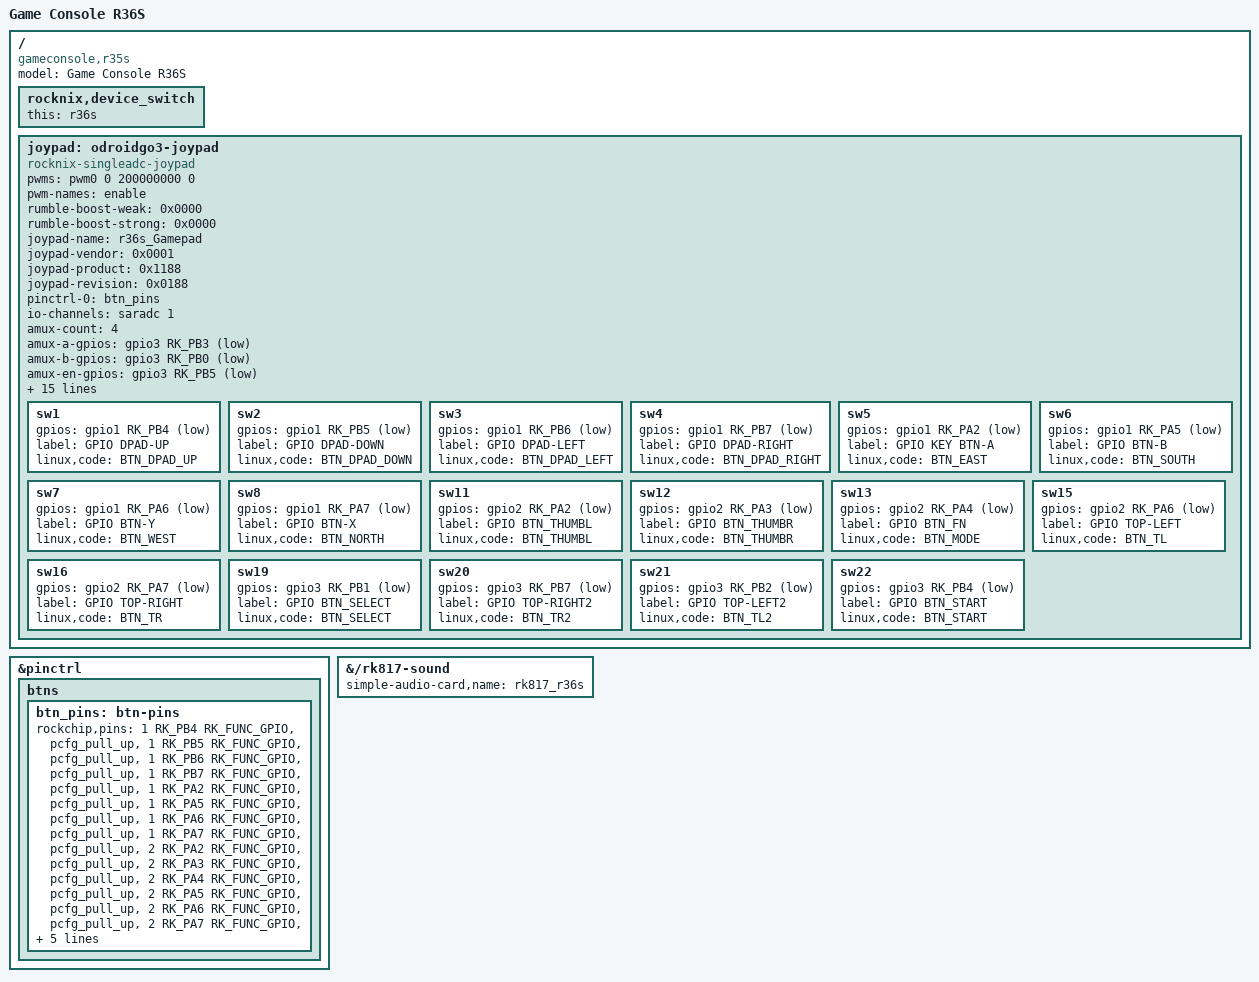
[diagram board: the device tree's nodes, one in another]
// SPDX-License-Identifier: (GPL-2.0+ OR MIT)
/*
 * # Copyright (C) 2022-24 JELOS (https://github.com/JustEnoughLinuxOS)
 */

/dts-v1/;
#include "rk3326-gameconsole-r3xs.dtsi"
#include "rk3326-device-group-r36.dtsi"

/ {
	model = "Game Console R36S";
	compatible = "gameconsole,r35s", "gameconsole,r36s", "rockchip,rk3326";

	rocknix,device_switch {
		this = "r36s";
	};

	joypad: odroidgo3-joypad {
                compatible = "rocknix-singleadc-joypad";
                pwms = <&pwm0 0 200000000 0>;		 
                pwm-names = "enable";
                rumble-boost-weak = <0x0000>;
                rumble-boost-strong = <0x0000>;
		 
                joypad-name = "r36s_Gamepad";
                joypad-vendor = <0x0001>;
                joypad-product = <0x1188>;
                joypad-revision = <0x0188>;

		status = "okay";

		/* gpio pincontrol setup */
                pinctrl-names = "default";
                pinctrl-0 = <&btn_pins>;

		/* Analog mux define */
		io-channel-names = "amux_adc";
		io-channels = <&saradc 1>;

		/* adc mux channel count */
		amux-count = <4>;
		/* adc mux select(a,b) gpio */
		amux-a-gpios = <&gpio3 RK_PB3 GPIO_ACTIVE_LOW>;
		amux-b-gpios = <&gpio3 RK_PB0 GPIO_ACTIVE_LOW>;
		/* adc mux enable gpio */
		amux-en-gpios = <&gpio3 RK_PB5 GPIO_ACTIVE_LOW>;

		/* adc calculate scale */
		button-adc-scale = <2>;

		/* adc deadzone range  */
		button-adc-deadzone = <64>;

		/*
		  specifies fuzz value that is used to filter noise from
		  the event stream.
		*/
		button-adc-fuzz = <32>;
		button-adc-flat = <32>;

		/*
		  Analog Stick data tuning value(precent)
		  p = positive direction, n = negative direction
		  report value = (real_adc_data * tuning_value) / 100
		*/
		/* batocera - the left stick falls short of full range on one side */
		abs_x-p-tuning = <300>;
		abs_x-n-tuning = <300>;

		abs_y-p-tuning = <300>;
		abs_y-n-tuning = <300>;

		abs_rx-p-tuning = <200>;
		abs_rx-n-tuning = <200>;

		abs_ry-p-tuning = <200>;
		abs_ry-n-tuning = <200>;

		/* poll device interval (ms), adc read interval */
		poll-interval = <10>;

		/* required for RG36S */
		invert-absx;
		invert-absy;
		
		/* gpio button auto repeat set value : default disable */
		/*
			autorepeat;
		*/

                /*
                    joypad driver is poll-device driver.
                    poll-device is does not support wakeup-source.
		*/
                sw1 {
                        gpios = <&gpio1 RK_PB4 GPIO_ACTIVE_LOW>;
                        label = "GPIO DPAD-UP";
                        linux,code = <BTN_DPAD_UP>; // 0x220
                };
                sw2 {
                        gpios = <&gpio1 RK_PB5 GPIO_ACTIVE_LOW>;
                        label = "GPIO DPAD-DOWN";
                        linux,code = <BTN_DPAD_DOWN>; // 0x221
                };
                sw3 {
                        gpios = <&gpio1 RK_PB6 GPIO_ACTIVE_LOW>;
                        label = "GPIO DPAD-LEFT";
                        linux,code = <BTN_DPAD_LEFT>; // 0x222
                };
                sw4 {
                        gpios = <&gpio1 RK_PB7 GPIO_ACTIVE_LOW>;
                        label = "GPIO DPAD-RIGHT";
                        linux,code = <BTN_DPAD_RIGHT>; // 0x223
                };
                sw5 {
                        gpios = <&gpio1 RK_PA2 GPIO_ACTIVE_LOW>;
                        label = "GPIO KEY BTN-A";
                        linux,code = <BTN_EAST>; // 0x131
                };
                sw6 {
                        gpios = <&gpio1 RK_PA5 GPIO_ACTIVE_LOW>;
                        label = "GPIO BTN-B";
                        linux,code = <BTN_SOUTH>; // 0x130
                };
                sw7 {
                        gpios = <&gpio1 RK_PA6 GPIO_ACTIVE_LOW>;
                        label = "GPIO BTN-Y";
                        linux,code = <BTN_WEST>; // 0x134
                };
                sw8 {
                        gpios = <&gpio1 RK_PA7 GPIO_ACTIVE_LOW>;
                        label = "GPIO BTN-X";
                        linux,code = <BTN_NORTH>; // 0x133
                };
                sw11 {
                        gpios = <&gpio2 RK_PA2 GPIO_ACTIVE_LOW>;
                        label = "GPIO BTN_THUMBL";
                        linux,code = <BTN_THUMBL>; // 0x2c2
                };
                sw12 {
                        gpios = <&gpio2 RK_PA3 GPIO_ACTIVE_LOW>;
                        label = "GPIO BTN_THUMBR";
                        linux,code = <BTN_THUMBR>; // 0x2c3
                };
                sw13 {
                        gpios = <&gpio2 RK_PA4 GPIO_ACTIVE_LOW>;
                        label = "GPIO BTN_FN";
                        linux,code = <BTN_MODE>; // 0x2c4
                };
                sw15 {
                        gpios = <&gpio2 RK_PA6 GPIO_ACTIVE_LOW>;
                        label = "GPIO TOP-LEFT";
                        linux,code = <BTN_TL>; // 0x02
                };
                sw16 {
                        gpios = <&gpio2 RK_PA7 GPIO_ACTIVE_LOW>;
                        label = "GPIO TOP-RIGHT";
                        linux,code = <BTN_TR>; // 0x05
                };
                sw19 {
                        gpios = <&gpio3 RK_PB1 GPIO_ACTIVE_LOW>;
                        label = "GPIO BTN_SELECT";
                        linux,code = <BTN_SELECT>;
                };
                sw20 {
                        gpios = <&gpio3 RK_PB7 GPIO_ACTIVE_LOW>;
                        label = "GPIO TOP-RIGHT2";
                        linux,code = <BTN_TR2>;
                };
                sw21 {
                        gpios = <&gpio3 RK_PB2 GPIO_ACTIVE_LOW>;
                        label = "GPIO TOP-LEFT2";
                        linux,code = <BTN_TL2>;
                };
                sw22 {
                        gpios = <&gpio3 RK_PB4 GPIO_ACTIVE_LOW>;
                        label = "GPIO BTN_START";
                        linux,code = <BTN_START>;
                };
        };
};

&pinctrl {
	btns {
		btn_pins: btn-pins {
			rockchip,pins = <1 RK_PB4 RK_FUNC_GPIO &pcfg_pull_up>,
					<1 RK_PB5 RK_FUNC_GPIO &pcfg_pull_up>,
					<1 RK_PB6 RK_FUNC_GPIO &pcfg_pull_up>,
					<1 RK_PB7 RK_FUNC_GPIO &pcfg_pull_up>,
					<1 RK_PA2 RK_FUNC_GPIO &pcfg_pull_up>,
					<1 RK_PA5 RK_FUNC_GPIO &pcfg_pull_up>,
					<1 RK_PA6 RK_FUNC_GPIO &pcfg_pull_up>,
					<1 RK_PA7 RK_FUNC_GPIO &pcfg_pull_up>,
					<2 RK_PA2 RK_FUNC_GPIO &pcfg_pull_up>,
					<2 RK_PA3 RK_FUNC_GPIO &pcfg_pull_up>,
					<2 RK_PA4 RK_FUNC_GPIO &pcfg_pull_up>,
					<2 RK_PA5 RK_FUNC_GPIO &pcfg_pull_up>,
					<2 RK_PA6 RK_FUNC_GPIO &pcfg_pull_up>,
					<2 RK_PA7 RK_FUNC_GPIO &pcfg_pull_up>,
					<3 RK_PB1 RK_FUNC_GPIO &pcfg_pull_up>,
					<3 RK_PB2 RK_FUNC_GPIO &pcfg_pull_up>,
					<3 RK_PB4 RK_FUNC_GPIO &pcfg_pull_up>,
					<3 RK_PB7 RK_FUNC_GPIO &pcfg_pull_up>;

		};
		
	};
};

/* batocera - own card name for the R36S speaker profile in alsa-ucm-conf */
&{/rk817-sound} {
	simple-audio-card,name = "rk817_r36s";
};
